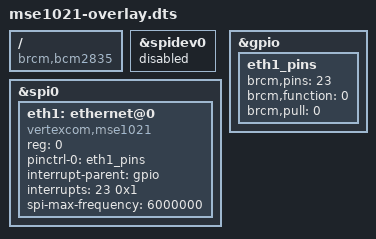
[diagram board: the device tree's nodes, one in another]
// Overlay for the Vertexcom MSE1021

/dts-v1/;
/plugin/;

/ {
	compatible = "brcm,bcm2835";

	fragment@0 {
		target = <&spidev0>;
		__overlay__ {
			status = "disabled";
		};
	};

	fragment@1 {
		target = <&spi0>;
		__overlay__ {
			#address-cells = <1>;
			#size-cells = <0>;
			status = "okay";

			eth1: ethernet@0 {
				compatible = "vertexcom,mse1021";
				reg = <0>; /* CE0 */
				pinctrl-names = "default";
				pinctrl-0 = <&eth1_pins>;
				interrupt-parent = <&gpio>;
				interrupts = <23 0x1>; /* rising edge */
				spi-max-frequency = <6000000>;
				status = "okay";
			};
		};
	};

	fragment@2 {
		target = <&gpio>;
		__overlay__ {
			eth1_pins: eth1_pins {
				brcm,pins = <23>;
				brcm,function = <0>; /* in */
				brcm,pull = <0>; /* none */
			};
		};
	};

	__overrides__ {
		int_pin = <&eth1>, "interrupts:0",
		          <&eth1_pins>, "brcm,pins:0";
		speed   = <&eth1>, "spi-max-frequency:0";
	};
};
